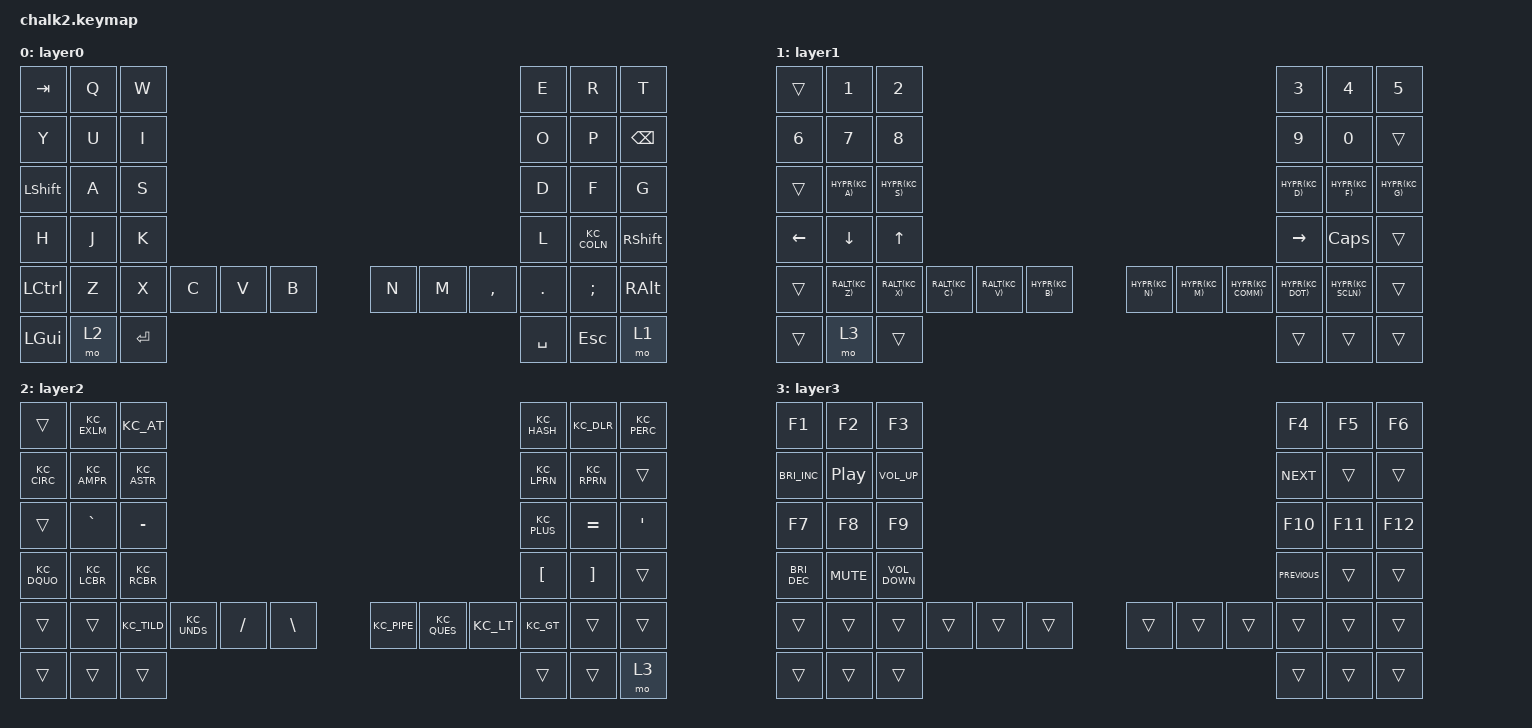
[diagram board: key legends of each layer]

  /*
  * Copyright (c) 2020 The ZMK Contributors
  *
  * SPDX-License-Identifier: MIT
  */

  #include <behaviors.dtsi>
  #include <dt-bindings/zmk/keys.h>
  #include <dt-bindings/zmk/bt.h>
  #include <dt-bindings/zmk/ext_power.h>

  / {
    keymap {
      compatible = "zmk,keymap";
  layer0 {
          bindings = <
          &kp TAB &kp Q &kp W &kp E &kp R &kp T              &kp Y &kp U &kp I &kp O &kp P &kp BACKSPACE
          &kp LEFT_SHIFT &kp A &kp S &kp D &kp F &kp G       &kp H &kp J &kp K &kp L [[KC_COLN]] &kp RIGHT_SHIFT 
          &kp LEFT_CONTROL &kp Z &kp X &kp C &kp V &kp B     &kp N &kp M &kp COMMA &kp DOT &kp SEMICOLON &kp RIGHT_ALT 
          &kp LEFT_GUI &mo 2 &kp ENTER                       &kp SPACE &kp ESCAPE &mo 1
          >;
        };layer1 {
          bindings = <
          &trans &kp N1 &kp N2 &kp N3 &kp N4 &kp N5          &kp N6 &kp N7 &kp N8 &kp N9 &kp N0 &trans 
          &trans [[HYPR(KC_A)]] [[HYPR(KC_S)]] [[HYPR(KC_D)]] [[HYPR(KC_F)]] [[HYPR(KC_G)]] 
                             &kp LEFT &kp DOWN &kp UP &kp RIGHT &kp CAPSLOCK &trans 
          &trans [[RALT(KC_Z)]] [[RALT(KC_X)]] [[RALT(KC_C)]] [[RALT(KC_V)]] [[HYPR(KC_B)]] 
                             [[HYPR(KC_N)]] [[HYPR(KC_M)]] [[HYPR(KC_COMM)]] [[HYPR(KC_DOT)]] [[HYPR(KC_SCLN)]] &trans 
          &trans &mo 3 &trans                                &trans &trans &trans
          >;
        };layer2 {
          bindings = <
          &trans [[KC_EXLM]] [[KC_AT]] [[KC_HASH]] [[KC_DLR]] [[KC_PERC]] 
                       [[KC_CIRC]] [[KC_AMPR]] [[KC_ASTR]] [[KC_LPRN]] [[KC_RPRN]] &trans 
          &trans &kp GRAVE &kp MINUS [[KC_PLUS]] &kp EQUAL &kp SINGLE_QUOTE 
                       [[KC_DQUO]] [[KC_LCBR]] [[KC_RCBR]] &kp LEFT_BRACKET &kp RIGHT_BRACKET &trans 
          &trans &trans [[KC_TILD]] [[KC_UNDS]] &kp SLASH &kp BACKSLASH 
                       [[KC_PIPE]] [[KC_QUES]] [[KC_LT]] [[KC_GT]] &trans &trans 
          &trans &trans &trans                               &trans &trans &mo 3
          >;
        };layer3 {
          bindings = <
          &kp F1 &kp F2 &kp F3 &kp F4 &kp F5 &kp F6 
                          &kp C_BRIGHTNESS_INC &kp C_PLAY_PAUSE &kp C_VOLUME_UP &kp C_NEXT &trans &trans 
          &kp F7 &kp F8 &kp F9 &kp F10 &kp F11 &kp F12 
                          &kp C_BRIGHTNESS_DEC &kp C_MUTE &kp C_VOLUME_DOWN &kp C_PREVIOUS &trans &trans 
          &trans &trans &trans &trans &trans &trans                  &trans &trans &trans &trans &trans &trans 
          &trans &trans &trans                                       &trans &trans &trans
          >;
        };
    };
  };
  
